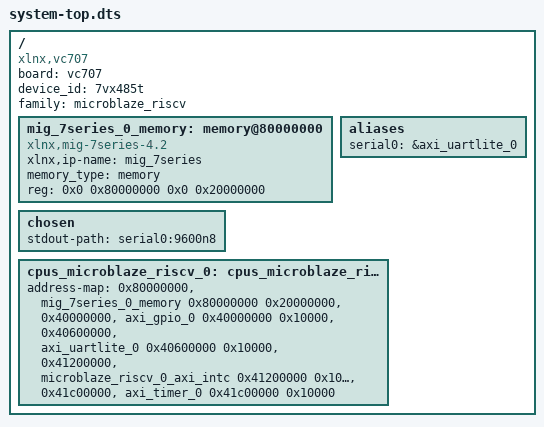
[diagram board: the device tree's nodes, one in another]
/dts-v1/;
#include "pl.dtsi"
/ {
	board = "vc707";
	compatible = "xlnx,vc707";
	device_id = "7vx485t";
	#address-cells = <1>;
	#size-cells = <1>;
	family = "microblaze_riscv";
	mig_7series_0_memory: memory@80000000 {
		compatible = "xlnx,mig-7series-4.2";
		xlnx,ip-name = "mig_7series";
		device_type = "memory";
		memory_type = "memory";
		reg = <0x0 0x80000000 0x0 0x20000000>;
	};
	chosen {
		stdout-path = "serial0:9600n8";
	};
	aliases {
		serial0 = &axi_uartlite_0;
	};
	cpus_microblaze_riscv_0: cpus_microblaze_riscv@0 {
		address-map = <0x80000000 &mig_7series_0_memory 0x80000000 0x20000000>, 
			      <0x40000000 &axi_gpio_0 0x40000000 0x10000>, 
			      <0x40600000 &axi_uartlite_0 0x40600000 0x10000>, 
			      <0x41200000 &microblaze_riscv_0_axi_intc 0x41200000 0x10000>, 
			      <0x41c00000 &axi_timer_0 0x41c00000 0x10000>;
		#ranges-address-cells = <0x1>;
		#ranges-size-cells = <0x1>;
	};
};
